# DCAN register map
Vendor: Texas Instruments
Peripheral module from a debugger description file (folder am335x).
Registers are 32-bit, read-only, no defined reset value unless marked. A register's access mark holds for its fields unless they carry their own. Offsets are as the file gives them; lines under a group give offsets from that group; [hi:lo] are bit positions; {n}, {i} and the like mark numbered series; 'fields as' and 'values as' point back to an identical list; <NAME> marks a mode.

## DCAN
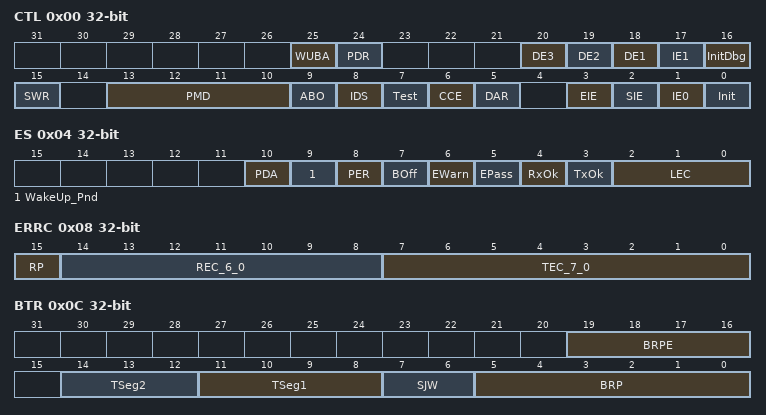
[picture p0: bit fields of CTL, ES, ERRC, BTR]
0x00 CTL access not given — The Bus-Off recovery sequence (refer to CAN specification) cannot be shortened by setting or resetting Init bit. If the module goes Bus-Off, it will automatically set the Init bit and stop all bus activities. When the Init bit is cleared by the application again, the module will then wait for 129 occurrences of Bus Idle (129 * 11 consecutive recessive bits) before resuming normal operation. At the end of the bus-off recovery sequence, the error counters will be reset. After the Init bit is reset, each time when a sequence of 11 recessive bits is monitored, a Bit0 error code is written to the error and status register, enabling the CPU to check whether the CAN bus is stuck at dominant or continuously disturbed, and to monitor the proceeding of the bus-off recovery sequence.
  [25] WUBA rw — Automatic wake up on bus activity when in local power-down mode. Note: The CAN message, which initiates the bus activity, cannot be received. This means that the first message received in power down and automatic wake-up mode, will be lost.
  [24] PDR rw — Request for local low power-down mode
  [20] DE3 rw — Enable DMA request line for IF3. Note: A pending DMA request for IF3 remains active until first access to one of the IF3 registers.
  [19] DE2 rw — Enable DMA request line for IF2. Note: A pending DMA request for IF2 remains active until first access to one of the IF2 registers.
  [18] DE1 rw — Enable DMA request line for IF1. Note: A pending DMA request for IF1 remains active until first access to one of the IF1 registers.
  [17] IE1 rw — Interrupt line 1 enable
  [16] InitDbg ro — Internal init state while debug access
  [15] SWR — SW reset enable. Note: To execute software reset, the following procedure is necessary: (a) Set Init bit to shut down CAN communication and (b) Set SWR bit additionally to Init bit. (access R/WP)
  [13:10] PMD rw — Parity on/off. 5 = Parity function disabled. Others = Parity function enabled.
  [9] ABO rw — Auto-Bus-On enable
  [8] IDS rw — Interruption debug support enable
  [7] Test rw — Test mode enable
  [6] CCE rw — Configuration change enable
  [5] DAR rw — Disable automatic retransmission
  [3] EIE rw — Error interrupt enable
  [2] SIE rw — Status change interrupt enable
  [1] IE0 rw — Interrupt line 0 enable
  [0] Init rw — Initialization
0x04 ES access not given — Interrupts are generated by bits PER, BOff and EWarn (if EIE bit in CAN control register is set) and by bits WakeUpPnd, RxOk, TxOk, and LEC (if SIE bit in CAN control register is set). A change of bit EPass will not generate an interrupt. Reading the error and status register clears the WakeUpPnd, PER, RxOk and TxOk bits and set the LEC to value '7.' Additionally, the status interrupt value (0x8000) in the interrupt register will be replaced by the next lower priority interrupt value. The EOI for all other interrupts (DCANINT0 and DCANINT1) are automatically handled by hardware. For debug support, the auto clear functionality of error and status register (clear of status flags by read) is disabled when in debug/suspend mode.
  [10] PDA ro — Local power-down mode acknowledge
  [9] WakeUp_Pnd — Wake up pending. This bit can be used by the CPU to identify the DCAN as the source to wake up the system. This bit will be reset if error and status register is read. (access R/C)
  [8] PER — Parity error detected. This bit will be reset if error and status register is read. (access R/C)
  [7] BOff ro — Bus-Off state
  [6] EWarn ro — Warning state
  [5] EPass ro — Error passive state
  [4] RxOk — Received a message successfully. This bit will be reset if error and status register is read. (access R/C)
  [3] TxOk — Transmitted a message successfully. This bit will be reset if error and status register is read. (access R/C)
  [2:0] LEC — Last error code. The LEC field indicates the type of the last error on the CAN bus. This field will be cleared to '0' when a message has been transferred (reception or transmission) without error. (access R/S)
0x08 ERRC
  [15] RP — Receive error passive
  [14:8] REC_6_0 — Receive error counter. Actual state of the receive error counter (values from 0 to 255).
  [7:0] TEC_7_0 — Transmit error counter. Actual state of the transmit error counter (values from 0 to 255).
0x0C BTR access not given — This register is only writable if CCE and Init bits in the CAN control register are set. The CAN bit time may be programmed in the range of 8 to 25 time quanta. The CAN time quantum may be programmed in the range of 1 to1024 CAN_CLK periods. With a CAN_CLK of 8 MHz and BRPE = 0x00, the reset value of 0x00002301 configures the DCAN for a bit rate of 500kBit/s.
  [19:16] BRPE ro — Baud rate prescaler extension. Valid programmed values are 0 to 15. By programming BRPE the baud rate prescaler can be extended to values up to 1024.
  [14:12] TSeg2 — Time segment after the sample point. Valid programmed values are 0 to 7. The actual TSeg2 value which is interpreted for the bit timing will be the programmed TSeg2 value + 1. (access R/WP)
  [11:8] TSeg1 — Time segment before the sample point. Valid programmed values are 1 to 15. The actual TSeg1 value interpreted for the bit timing will be the programmed TSeg1 value + 1. (access R/WP)
  [7:6] SJW — Synchronization Jump Width. Valid programmed values are 0 to 3. The actual SJW value interpreted for the synchronization will be the programmed SJW value + 1. (access R/WP)
  [5:0] BRP — Baud rate prescaler. Value by which the CAN_CLK frequency is divided for generating the bit time quanta. The bit time is built up from a multiple of this quanta. Valid programmed values are 0 to 63. The actual BRP value interpreted for the bit timing will be the programmed BRP value + 1. (access R/WP)
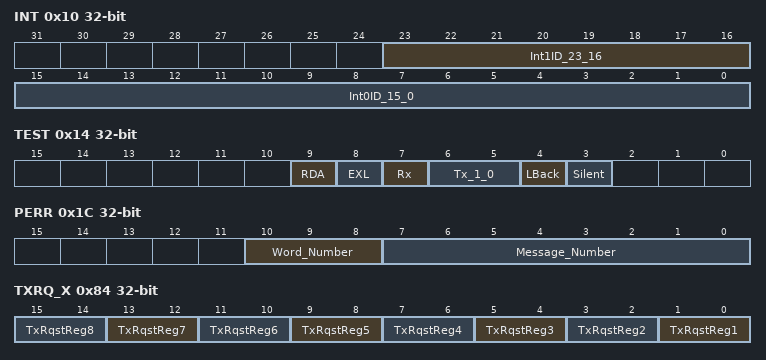
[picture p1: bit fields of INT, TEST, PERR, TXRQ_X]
0x10 INT
  [23:16] Int1ID_23_16 — Interrupt 1 Identifier (indicates the message object with the highest pending interrupt). If several interrupts are pending, the CAN interrupt register will point to the pending interrupt with the highest priority. The DCAN1INT interrupt line remains active until Int1ID reaches value 0 (the cause of the interrupt is reset) or until IE1 is cleared. A message interrupt is cleared by clearing the message object's IntPnd bit. Among the message interrupts, the message object's interrupt priority decreases with increasing message number.
  [15:0] Int0ID_15_0 — Interrupt Identifier (the number here indicates the source of the interrupt). If several interrupts are pending, the CAN interrupt register will point to the pending interrupt with the highest priority. The DCAN0INT interrupt line remains active until Int0ID reaches value 0 (the cause of the interrupt is reset) or until IE0 is cleared. The Status interrupt has the highest priority. Among the message interrupts, the message object's interrupt priority decreases with increasing message number.
0x14 TEST access not given — For all test modes, the test bit in CAN control register needs to be set to one. If test bit is set, the RDA, EXL, Tx1, Tx0, LBack and Silent bits are writable. Bit Rx monitors the state of pin CAN_RX and therefore is only readable. All test register functions are disabled when test bit is cleared. The test register is only writable if test bit in CAN control register is set. Setting Tx[1:0] other than '00' will disturb message transfer. When the internal loop-back mode is active (bit LBack is set), bit EXL will be ignored.
  [9] RDA — RAM direct access enable (access R/WP)
  [8] EXL — External loopback mode (access R/WP)
  [7] Rx ro — Receive pin. Monitors the actual value of the CAN_RX pin
  [6:5] Tx_1_0 — Control of CAN_TX pin. (access R/WP)
  [4] LBack — Loopback mode (access R/WP)
  [3] Silent — Silent mode (access R/WP)
0x1C PERR — If a parity error is detected, the PER flag will be set in the error and status register. This bit is not reset by the parity check mechanism; it must be reset by reading the error and status register. In addition to the PER flag, the parity error code register will indicate the memory area where the parity error has been detected (message number and word number). If more than one word with a parity error was detected, the highest word number with a parity error will be displayed. After a parity error has been detected, the register will hold the last error code until power is removed.
  [10:8] Word_Number — Word number where parity error has been detected.
  [7:0] Message_Number
0x80 ABOTR rw — On write access to the CAN control register while Auto-Bus-On timer is running, the Auto-Bus-On procedure will be aborted. During Debug/Suspend mode, running Auto-Bus-On timer will be paused.
  [31:0] ABO_Time — Number of OCP clock cycles before a Bus-Off recovery sequence is started by clearing the Init bit. This function has to be enabled by setting bit ABO in CAN control register. The Auto-Bus-On timer is realized by a 32 bit counter that starts to count down to zero when the module goes Bus-Off. The counter will be reloaded with the preload value of the ABO time register after this phase.
0x84 TXRQ_X — Example 1. Bit 0 of the transmission request X register represents byte 0 of the transmission request 1 register. If one or more bits in this byte are set, bit 0 of the transmission request X register will be set.
  [2n-1:2n-2] TxRqstReg{n} (n=1..8)
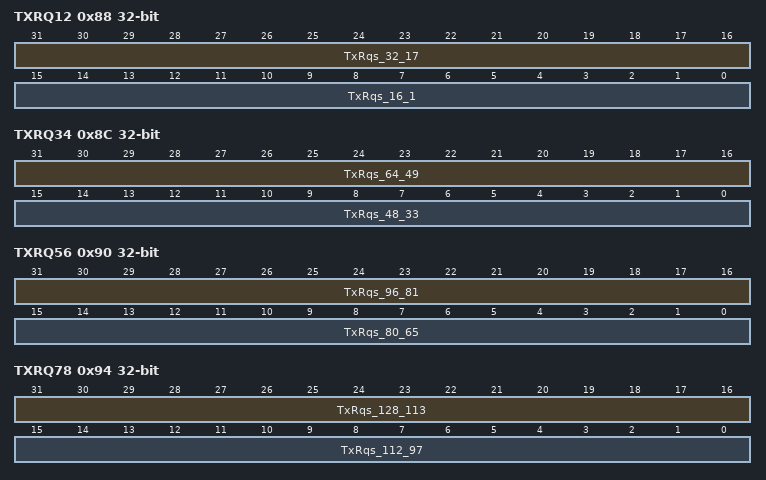
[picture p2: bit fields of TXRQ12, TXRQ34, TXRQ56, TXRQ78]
0x88 TXRQ12 — The TXRQ12 to TXRQ78 registers hold the TxRqst bits of the implemented message objects. By reading out these bits, the CPU can check for pending transmission requests. The TxRqst bit in a specific message object can be set/reset by the CPU via the IF1/IF2 message interface registers, or by the message handler after reception of a remote frame or after a successful transmission.
  [31:16] TxRqs_32_17 — Transmission request bits (for all message objects)
  [15:0] TxRqs_16_1 — Transmission request bits (for all message objects)
0x8C TXRQ34 — The TXRQ12 to TXRQ78 registers hold the TxRqst bits of the implemented message objects. By reading out these bits, the CPU can check for pending transmission requests. The TxRqst bit in a specific message object can be set/reset by the CPU via the IF1/IF2 message interface registers, or by the message handler after reception of a remote frame or after a successful transmission.
  [31:16] TxRqs_64_49 — Transmission request bits (for all message objects)
  [15:0] TxRqs_48_33 — Transmission request bits (for all message objects)
0x90 TXRQ56 — The TXRQ12 to TXRQ78 registers hold the TxRqst bits of the implemented message objects. By reading out these bits, the CPU can check for pending transmission requests. The TxRqst bit in a specific message object can be set/reset by the CPU via the IF1/IF2 message interface registers, or by the message handler after reception of a remote frame or after a successful transmission.
  [31:16] TxRqs_96_81 — Transmission request bits (for all message objects)
  [15:0] TxRqs_80_65 — Transmission request bits (for all message objects)
0x94 TXRQ78 — The TXRQ12 to TXRQ78 registers hold the TxRqst bits of the implemented message objects. By reading out these bits, the CPU can check for pending transmission requests. The TxRqst bit in a specific message object can be set/reset by the CPU via the IF1/IF2 message interface registers, or by the message handler after reception of a remote frame or after a successful transmission.
  [31:16] TxRqs_128_113 — Transmission request bits (for all message objects)
  [15:0] TxRqs_112_97 — Transmission request bits (for all message objects)
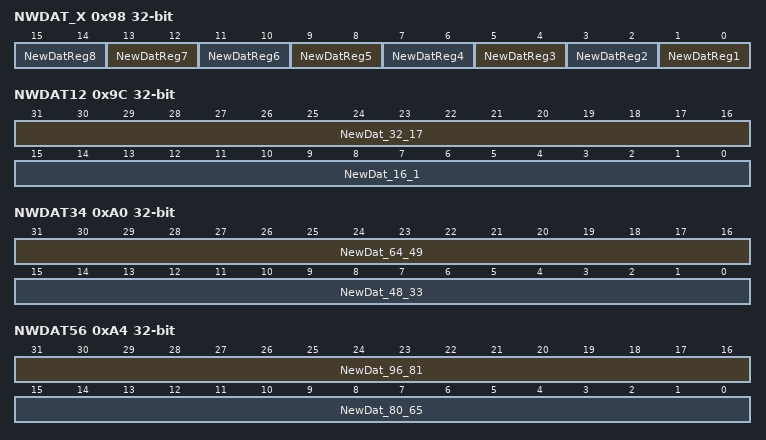
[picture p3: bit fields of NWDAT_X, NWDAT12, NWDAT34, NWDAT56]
0x98 NWDAT_X — With the new data X register, the CPU can detect if one or more bits in the different new data registers are set. Each register bit represents a group of eight message objects. If at least on of the NewDat bits of these message objects are set, the corresponding bit in the new data X register will be set. Example 1. Bit 0 of the new data X register represents byte 0 of the new data 1 register. If one or more bits in this byte are set, bit 0 of the new data X register will be set.
  [2n-1:2n-2] NewDatReg{n} (n=1..8)
0x9C NWDAT12 — These registers hold the NewDat bits of the implemented message objects. By reading out these bits, the CPU can check for new data in the message objects. The NewDat bit of a specific message object can be set/reset by the CPU via the IF1/IF2 interface register sets, or by the message handler after reception of a data frame or after a successful transmission.
  [31:16] NewDat_32_17 — New Data Bits (for all message objects)
  [15:0] NewDat_16_1 — New Data Bits (for all message objects)
0xA0 NWDAT34 — These registers hold the NewDat bits of the implemented message objects. By reading out these bits, the CPU can check for new data in the message objects. The NewDat bit of a specific message object can be set/reset by the CPU via the IF1/IF2 interface register sets, or by the message handler after reception of a data frame or after a successful transmission.
  [31:16] NewDat_64_49 — New Data Bits (for all message objects)
  [15:0] NewDat_48_33 — New Data Bits (for all message objects)
0xA4 NWDAT56 — These registers hold the NewDat bits of the implemented message objects. By reading out these bits, the CPU can check for new data in the message objects. The NewDat bit of a specific message object can be set/reset by the CPU via the IF1/IF2 interface register sets, or by the message handler after reception of a data frame or after a successful transmission.
  [31:16] NewDat_96_81 — New Data Bits (for all message objects)
  [15:0] NewDat_80_65 — New Data Bits (for all message objects)
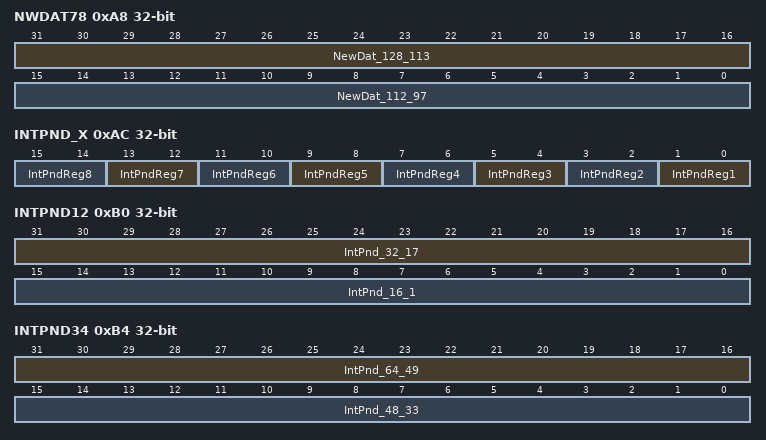
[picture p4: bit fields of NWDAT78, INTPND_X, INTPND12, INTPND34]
0xA8 NWDAT78 — These registers hold the NewDat bits of the implemented message objects. By reading out these bits, the CPU can check for new data in the message objects. The NewDat bit of a specific message object can be set/reset by the CPU via the IF1/IF2 interface register sets, or by the message handler after reception of a data frame or after a successful transmission.
  [31:16] NewDat_128_113 — New Data Bits (for all message objects)
  [15:0] NewDat_112_97 — New Data Bits (for all message objects)
0xAC INTPND_X — With the interrupt pending X register, the CPU can detect if one or more bits in the different interrupt pending registers are set. Each bit of this register represents a group of eight message objects. If at least one of the IntPnd bits of these message objects are set, the corresponding bit in the interrupt pending X register will be set. Example 2. Bit 0 of the interrupt pending X register represents byte 0 of the interrupt pending 1 register. If one or more bits in this byte are set, bit 0 of the interrupt pending X register will be set.
  [2n-1:2n-2] IntPndReg{n} (n=1..8)
0xB0 INTPND12 — These registers hold the IntPnd bits of the implemented message objects. By reading out these bits, the CPU can check for pending interrupts in the message objects. The IntPnd bit of a specific message object can be set/reset by the CPU via the IF1/IF2 interface register sets, or by the message handler after a reception or a successful transmission.
  [31:16] IntPnd_32_17 — Interrupt Pending Bits (for all message objects)
  [15:0] IntPnd_16_1 — Interrupt Pending Bits (for all message objects)
0xB4 INTPND34 — These registers hold the IntPnd bits of the implemented message objects. By reading out these bits, the CPU can check for pending interrupts in the message objects. The IntPnd bit of a specific message object can be set/reset by the CPU via the IF1/IF2 interface register sets, or by the message handler after a reception or a successful transmission.
  [31:16] IntPnd_64_49 — Interrupt Pending Bits (for all message objects)
  [15:0] IntPnd_48_33 — Interrupt Pending Bits (for all message objects)
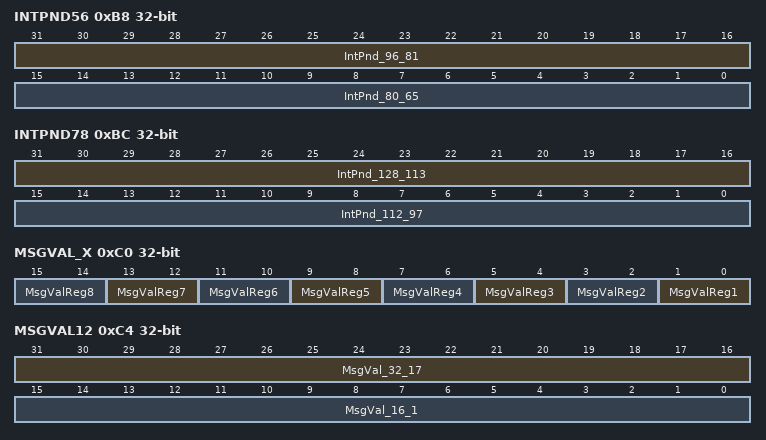
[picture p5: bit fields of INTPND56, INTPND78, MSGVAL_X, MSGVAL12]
0xB8 INTPND56 — These registers hold the IntPnd bits of the implemented message objects. By reading out these bits, the CPU can check for pending interrupts in the message objects. The IntPnd bit of a specific message object can be set/reset by the CPU via the IF1/IF2 interface register sets, or by the message handler after a reception or a successful transmission.
  [31:16] IntPnd_96_81 — Interrupt Pending Bits (for all message objects)
  [15:0] IntPnd_80_65 — Interrupt Pending Bits (for all message objects)
0xBC INTPND78 — These registers hold the IntPnd bits of the implemented message objects. By reading out these bits, the CPU can check for pending interrupts in the message objects. The IntPnd bit of a specific message object can be set/reset by the CPU via the IF1/IF2 interface register sets, or by the message handler after a reception or a successful transmission.
  [31:16] IntPnd_128_113 — Interrupt Pending Bits (for all message objects)
  [15:0] IntPnd_112_97 — Interrupt Pending Bits (for all message objects)
0xC0 MSGVAL_X — With the message valid X register, the CPU can detect if one or more bits in the different message valid registers are set. Each bit of this register represents a group of eight message objects. If at least one of the MsgVal bits of these message objects are set, the corresponding bit in the message valid X register will be set. Example 3. Bit 0 of the message valid X register represents byte 0 of the message valid 1 register. If one or more bits in this byte are set, bit 0 of the message valid X register will be set.
  [2n-1:2n-2] MsgValReg{n} (n=1..8)
0xC4 MSGVAL12 — These registers hold the MsgVal bits of the implemented message objects. By reading out these bits, the CPU can check which message objects are valid. The MsgVal bit of a specific message object can be set/reset by the CPU via the IF1/IF2 interface register sets, or by the message handler after a reception or a successful transmission.
  [31:16] MsgVal_32_17 — Message valid bits (for all message objects)
  [15:0] MsgVal_16_1 — Message valid bits (for all message objects)
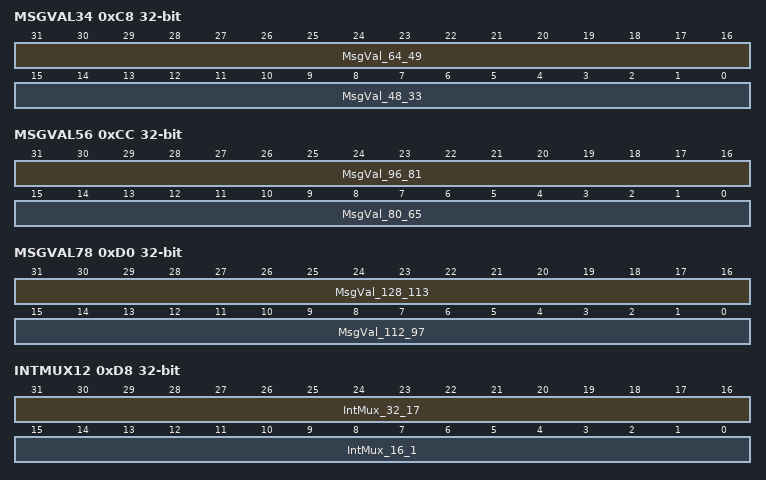
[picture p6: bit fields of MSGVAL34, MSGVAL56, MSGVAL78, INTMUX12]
0xC8 MSGVAL34 — These registers hold the MsgVal bits of the implemented message objects. By reading out these bits, the CPU can check which message objects are valid. The MsgVal bit of a specific message object can be set/reset by the CPU via the IF1/IF2 interface register sets, or by the message handler after a reception or a successful transmission.
  [31:16] MsgVal_64_49 — Message valid bits (for all message objects)
  [15:0] MsgVal_48_33 — Message valid bits (for all message objects)
0xCC MSGVAL56 — These registers hold the MsgVal bits of the implemented message objects. By reading out these bits, the CPU can check which message objects are valid. The MsgVal bit of a specific message object can be set/reset by the CPU via the IF1/IF2 interface register sets, or by the message handler after a reception or a successful transmission.
  [31:16] MsgVal_96_81 — Message valid bits (for all message objects)
  [15:0] MsgVal_80_65 — Message valid bits (for all message objects)
0xD0 MSGVAL78 — These registers hold the MsgVal bits of the implemented message objects. By reading out these bits, the CPU can check which message objects are valid. The MsgVal bit of a specific message object can be set/reset by the CPU via the IF1/IF2 interface register sets, or by the message handler after a reception or a successful transmission.
  [31:16] MsgVal_128_113 — Message valid bits (for all message objects)
  [15:0] MsgVal_112_97 — Message valid bits (for all message objects)
0xD8 INTMUX12 — The IntMux flag determine for each message object, which of the two interrupt lines (DCAN0INT or DCAN1INT) will be asserted when the IntPnd of this message object is set. Both interrupt lines can be globally enabled or disabled by setting or clearing IE0 and IE1 bits in CAN control register. The IntPnd bit of a specific message object can be set or reset by the CPU via the IF1/IF2 interface register sets, or by message handler after reception or successful transmission of a frame. This will also affect the Int0ID resp Int1ID flags in the interrupt register.
  [31:16] IntMux_32_17 — Multiplexes IntPnd value to either DCAN0INT or DCAN1INT interrupt lines (for all message objects)
  [15:0] IntMux_16_1 — Multiplexes IntPnd value to either DCAN0INT or DCAN1INT interrupt lines (for all message objects)
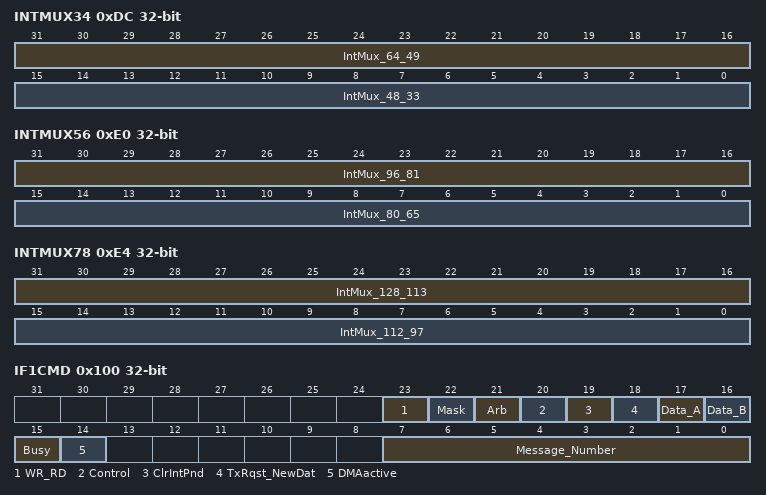
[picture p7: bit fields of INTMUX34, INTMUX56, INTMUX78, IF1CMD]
0xDC INTMUX34 — The IntMux flag determine for each message object, which of the two interrupt lines (DCAN0INT or DCAN1INT) will be asserted when the IntPnd of this message object is set. Both interrupt lines can be globally enabled or disabled by setting or clearing IE0 and IE1 bits in CAN control register. The IntPnd bit of a specific message object can be set or reset by the CPU via the IF1/IF2 interface register sets, or by message handler after reception or successful transmission of a frame. This will also affect the Int0ID resp Int1ID flags in the interrupt register.
  [31:16] IntMux_64_49 — Multiplexes IntPnd value to either DCAN0INT or DCAN1INT interrupt lines (for all message objects)
  [15:0] IntMux_48_33 — Multiplexes IntPnd value to either DCAN0INT or DCAN1INT interrupt lines (for all message objects)
0xE0 INTMUX56 — The IntMux flag determine for each message object, which of the two interrupt lines (DCAN0INT or DCAN1INT) will be asserted when the IntPnd of this message object is set. Both interrupt lines can be globally enabled or disabled by setting or clearing IE0 and IE1 bits in CAN control register. The IntPnd bit of a specific message object can be set or reset by the CPU via the IF1/IF2 interface register sets, or by message handler after reception or successful transmission of a frame. This will also affect the Int0ID resp Int1ID flags in the interrupt register.
  [31:16] IntMux_96_81 — Multiplexes IntPnd value to either DCAN0INT or DCAN1INT interrupt lines (for all message objects)
  [15:0] IntMux_80_65 — Multiplexes IntPnd value to either DCAN0INT or DCAN1INT interrupt lines (for all message objects)
0xE4 INTMUX78 — The IntMux flag determine for each message object, which of the two interrupt lines (DCAN0INT or DCAN1INT) will be asserted when the IntPnd of this message object is set. Both interrupt lines can be globally enabled or disabled by setting or clearing IE0 and IE1 bits in CAN control register. The IntPnd bit of a specific message object can be set or reset by the CPU via the IF1/IF2 interface register sets, or by message handler after reception or successful transmission of a frame. This will also affect the Int0ID resp Int1ID flags in the interrupt register.
  [31:16] IntMux_128_113 — Multiplexes IntPnd value to either DCAN0INT or DCAN1INT interrupt lines (for all message objects)
  [15:0] IntMux_112_97 — Multiplexes IntPnd value to either DCAN0INT or DCAN1INT interrupt lines (for all message objects)
0x100 IF1CMD access not given — The IF1 Command Register (IF1CMD) configures and initiates the transfer between the IF1 register sets and the message RAM. It is configurable which portions of the message object should be transferred. A transfer is started when the CPU writes the message number to bits [7:0] of the IF1 command register. With this write operation, the Busy bit is automatically set to '1' to indicate that a transfer is in progress. After 4 to 14 OCP clock cycles, the transfer between the interface register and the message RAM will be completed and the Busy bit is cleared. The maximum number of cycles is needed when the message transfer concurs with a CAN message transmission, acceptance filtering, or message storage. If the CPU writes to both IF1 command registers consecutively (request of a second transfer while first transfer is still in progress), the second transfer will start after the first one has been completed. While Busy bit is one, IF1 register sets are write protected. For debug support, the auto clear functionality of the IF1 command registers (clear of DMAactive flag by r/w) is disabled during Debug/Suspend mode. If an invalid Message Number is written to bits [7:0] of the IF1 command register, the message handler may access an implemented (valid) message object instead.
  [23] WR_RD — Write/Read (access R/WP)
  [22] Mask — Access mask bits (access R/WP)
  [21] Arb — Access arbitration bits (access R/WP)
  [20] Control — Access control bits. If the TxRqst/NewDat bit in this register(Bit [18]) is set, the TxRqst/ NewDat bit in the IF1 message control register will be ignored. (access R/WP)
  [19] ClrIntPnd — Clear interrupt pending bit (access R/WP)
  [18] TxRqst_NewDat — Access transmission request bit. Note: If a CAN transmission is requested by setting TxRqst/NewDat in this register, the TxRqst/NewDat bits in the message object will be set to one independent of the values in IF1 message control Register. Note: A read access to a message object can be combined with the reset of the control bits IntPnd and NewDat. The values of these bits transferred to the IF1 message control register always reflect the status before resetting them. (access R/WP)
  [17] Data_A — Access Data Bytes 0 to 3. (access R/WP)
  [16] Data_B — Access Data Bytes 4 to 7. (access R/WP)
  [15] Busy — Busy flag. This bit is set to one after the message number has been written to bits 7 to 0. IF1 register set will be write protected. The bit is cleared after read/write action has been finished. (access R/WP)
  [14] DMAactive — Activation of DMA feature for subsequent internal IF1 update. Note: Due to the auto reset feature of the DMAactive bit, this bit has to be set for each subsequent DMA cycle separately. (access R/WP)
  [7:0] Message_Number — Number of message object in message RAM which is used for data transfer. (access R/WP)
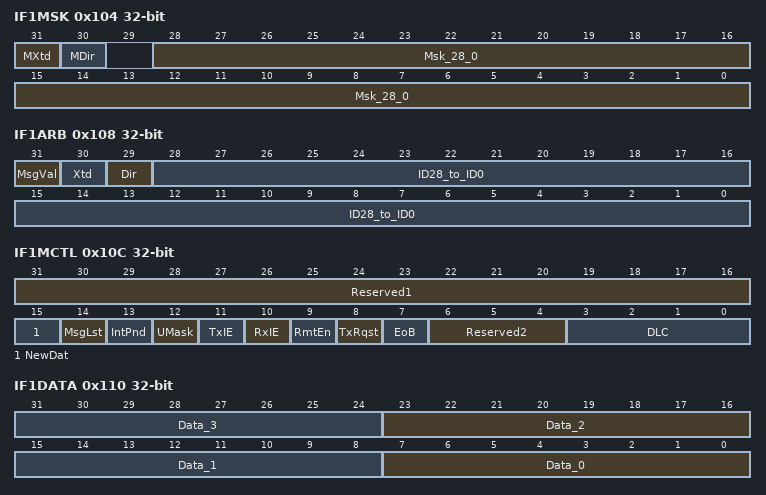
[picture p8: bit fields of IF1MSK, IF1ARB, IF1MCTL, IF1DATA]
0x104 IF1MSK access not given — The bits of the IF1 mask registers mirror the mask bits of a message object. While Busy bit of IF1 command register is one, IF1 register set is write protected.
  [31] MXtd — Mask Extended Identifier. When 11 bit (standard) identifiers are used for a message object, the identifiers of received data frames are written into bits ID28 to ID18. For acceptance filtering, only these bits together with mask bits Msk28 to Msk18 are considered. (access R/WP)
  [30] MDir — Mask Message Direction (access R/WP)
  [28:0] Msk_28_0 — Identifier Mask (access R/WP)
0x108 IF1ARB access not given — The bits of the IF1 arbitration registers mirror the arbitration bits of a message object. While Busy bit of IF1 command register is one, IF1 register set is write protected.
  [31] MsgVal — Message valid. The CPU should reset the MsgVal bit of all unused Messages Objects during the initialization before it resets bit Init in the CAN control register. This bit must also be reset before the identifier ID28 to ID0, the control bits Xtd, Dir or DLC3 to DLC0 are modified, or if the messages object is no longer required. (access R/WP)
  [30] Xtd — Extended identifier (access R/WP)
  [29] Dir — Message direction (access R/WP)
  [28:0] ID28_to_ID0 — Message identifier. ID28 to ID0 is equal to 29 bit identifier (extended frame) ID28 to ID18 is equal to 11 bit identifier (standard frame) (access R/WP)
0x10C IF1MCTL access not given — The bits of the IF1 message control registers mirror the message control bits of a message object. While Busy bit of IF1 command register is one, IF1 register set is write protected.
  [31:16] Reserved1 — (access R/WP)
  [15] NewDat — New data (access R/WP)
  [14] MsgLst — Message lost (only valid for message objects with direction = receive) (access R/WP)
  [13] IntPnd — Interrupt pending (access R/WP)
  [12] UMask — Use acceptance mask. If the UMask bit is set to one, the message object's mask bits have to be programmed during initialization of the message object before MsgVal is set to one. (access R/WP)
  [11] TxIE — Transmit interrupt enable (access R/WP)
  [10] RxIE — Receive interrupt enable (access R/WP)
  [9] RmtEn — Remote enable (access R/WP)
  [8] TxRqst — Transmit request (access R/WP)
  [7] EoB — Data frame has 0 to 8 data bits. Note: This bit is used to concatenate multiple message objects to build a FIFO Buffer. For single message objects (not belonging to a FIFO Buffer), this bit must always be set to one. (access R/WP)
  [6:4] Reserved2 — (access R/WP)
  [3:0] DLC — Data length code. Note: The data length code of a message object must be defined the same as in all the corresponding objects with the same identifier at other nodes. When the message handler stores a data frame, it will write the DLC to the value given by the received message. (access R/WP)
0x110 IF1DATA access not given — The data bytes of CAN messages are stored in the IF1 registers in the following order: (1) In a CAN data frame, Data 0 is the first, and Data 7 is the last byte to be transmitted or received. (2) In CAN's serial bit stream, the MSB of each byte will be transmitted first.
  [8n+7:8n] Data_{n} (n=0..3) — Data {n}. (access R/WP)
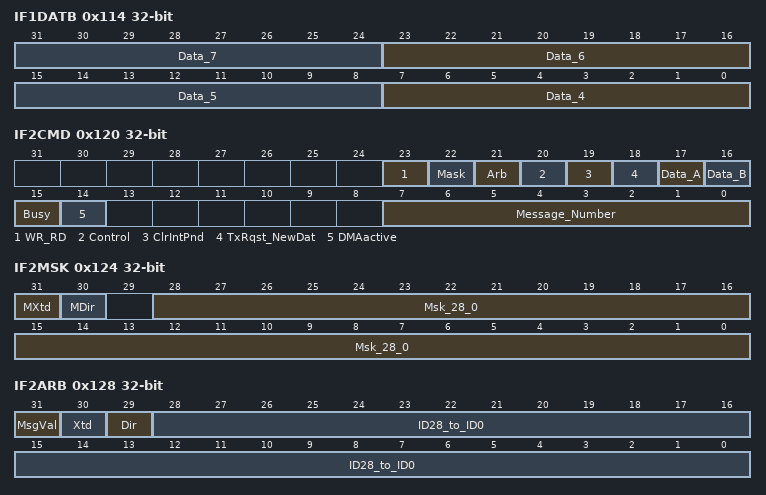
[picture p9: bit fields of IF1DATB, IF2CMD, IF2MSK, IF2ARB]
0x114 IF1DATB access not given — The data bytes of CAN messages are stored in the IF1 registers in the following order: (1) In a CAN data frame, Data 0 is the first, and Data 7 is the last byte to be transmitted or received. (2) In CAN's serial bit stream, the MSB of each byte will be transmitted first.
  [8n-25:8n-32] Data_{n} (n=4..7) — Data {n}. (access R/WP)
0x120 IF2CMD access not given — The IF2 Command Register (IF1CMD) configures and initiates the transfer between the IF2 register sets and the message RAM. It is configurable which portions of the message object should be transferred. A transfer is started when the CPU writes the message number to bits [7:0] of the IF2 command register. With this write operation, the Busy bit is automatically set to '1' to indicate that a transfer is in progress. After 4 to 14 OCP clock cycles, the transfer between the interface register and the message RAM will be completed and the Busy bit is cleared. The maximum number of cycles is needed when the message transfer concurs with a CAN message transmission, acceptance filtering, or message storage. If the CPU writes to both IF2 command registers consecutively (request of a second transfer while first transfer is still in progress), the second transfer will start after the first one has been completed. While Busy bit is one, IF2 register sets are write protected. For debug support, the auto clear functionality of the IF2 command registers (clear of DMAactive flag by r/w) is disabled during Debug/Suspend mode. If an invalid Message Number is written to bits [7:0] of the IF2 command register, the message handler may access an implemented (valid) message object instead.
  [23] WR_RD — Write/Read (access R/WP)
  [22] Mask — Access mask bits (access R/WP)
  [21] Arb — Access arbitration bits (access R/WP)
  [20] Control — Access control bits. If the TxRqst/NewDat bit in this register(Bit [18]) is set, the TxRqst/ NewDat bit in the IF2 message control register will be ignored. (access R/WP)
  [19] ClrIntPnd — Clear interrupt pending bit (access R/WP)
  [18] TxRqst_NewDat — Access transmission request bit. Note: If a CAN transmission is requested by setting TxRqst/NewDat in this register, the TxRqst/NewDat bits in the message object will be set to one independent of the values in IF2 message control Register. Note: A read access to a message object can be combined with the reset of the control bits IntPnd and NewDat. The values of these bits transferred to the IF2 message control register always reflect the status before resetting them. (access R/WP)
  [17] Data_A — Access Data Bytes 0 to 3. (access R/WP)
  [16] Data_B — Access Data Bytes 4 to 7. (access R/WP)
  [15] Busy — Busy flag. This bit is set to one after the message number has been written to bits 7 to 0. IF2 register set will be write protected. The bit is cleared after read/write action has been finished. (access R/WP)
  [14] DMAactive — Activation of DMA feature for subsequent internal IF2 update. Note: Due to the auto reset feature of the DMAactive bit, this bit has to be set for each subsequent DMA cycle separately. (access R/WP)
  [7:0] Message_Number — Number of message object in message RAM which is used for data transfer. (access R/WP)
0x124 IF2MSK access not given — The bits of the IF2 mask registers mirror the mask bits of a message object. While Busy bit of IF2 command register is one, IF2 register set is write protected.
  fields as IF1MSK
0x128 IF2ARB access not given — The bits of the IF2 arbitration registers mirror the arbitration bits of a message object. While Busy bit of IF2 command register is one, IF2 register set is write protected.
  [31] MsgVal — Message valid. The CPU should reset the MsgVal bit of all unused Messages Objects during the initialization before it resets bit Init in the CAN control register. This bit must also be reset before the identifier ID28 to ID0, the control bits Xtd, Dir or DLC3 to DLC0 are modified, or if the messages object is no longer required. (access R/WP)
  [30] Xtd — Extended identifier (access R/WP)
  [29] Dir — Message direction (access R/WP)
  [28:0] ID28_to_ID0 — Message identifier. ID28 to ID0 is equal to 29-bit identifier (extended frame) ID28 to ID18 is equal to 11-bit identifier (standard frame) (access R/WP)
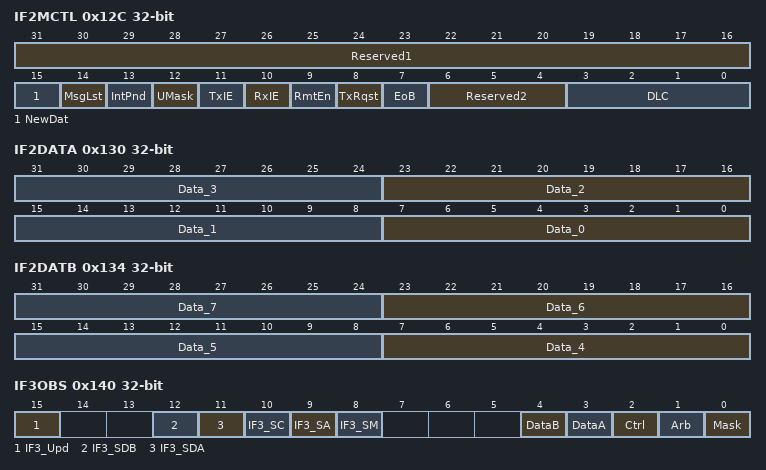
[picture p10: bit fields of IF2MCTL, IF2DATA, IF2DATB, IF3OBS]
0x12C IF2MCTL access not given — The bits of the IF2 message control registers mirror the message control bits of a message object. While Busy bit of IF2 command register is one, IF2 register set is write protected.
  fields as IF1MCTL
0x130 IF2DATA access not given — The data bytes of CAN messages are stored in the IF2 registers in the following order: (1) In a CAN data frame, Data 0 is the first, and Data 7 is the last byte to be transmitted or received. (2) In CAN's serial bit stream, the MSB of each byte will be transmitted first.
  [8n+7:8n] Data_{n} (n=0..3) — Data {n}. (access R/WP)
0x134 IF2DATB access not given — The data bytes of CAN messages are stored in the IF2 registers in the following order: (1) In a CAN data frame, Data 0 is the first, and Data 7 is the last byte to be transmitted or received. (2) In CAN's serial bit stream, the MSB of each byte will be transmitted first.
  [8n-25:8n-32] Data_{n} (n=4..7) — Data {n}. (access R/WP)
0x140 IF3OBS access per field — The IF3 register set can automatically be updated with received message objects without the need to initiate the transfer from message RAM by CPU. The observation flags (Bits [4:0]) in the IF3 observation register are used to determine, which data sections of the IF3 interface register set have to be read in order to complete a DMA read cycle. After all marked data sections are read, the DCAN is enabled to update the IF3 interface register set with new data. Any access order of single bytes or half-words is supported. When using byte or half-word accesses, a data section is marked as completed, if all bytes are read. Note: If IF3 Update Enable is used and no Observation flag is set, the corresponding message objects will be copied to IF3 without activating the DMA request line and without waiting for DMA read accesses. A write access to this register aborts a pending DMA cycle by resetting the DMA line and enables updating of IF3 interface register set with new data. To avoid data inconsistency, the DMA controller should be disabled before reconfiguring IF3 observation register. The status of the current read-cycle can be observed via status flags (Bits [12:8]). If an interrupt line is available for IF3, an interrupt will be generated by IF3Upd flag. See the device-specific data sheet for the availability of this interrupt source. With this interrupt, the observation status bits and the IF3Upd bit could be used by the application to realize the notification about new IF3 content in polling or interrupt mode.
  [15] IF3_Upd ro — IF3 Update Data
  [12] IF3_SDB ro — IF3 Status of Data B read access
  [11] IF3_SDA ro — IF3 Status of Data A read access
  [10] IF3_SC ro — IF3 Status of control bits read access
  [9] IF3_SA ro — IF3 Status of Arbitration data read access
  [8] IF3_SM ro — IF3 Status of Mask data read access
  [4] DataB rw — Data B read observation
  [3] DataA rw — Data A read observation
  [2] Ctrl rw — Ctrl read observation
  [1] Arb rw — Arbitration data read observation
  [0] Mask rw — Mask data read observation
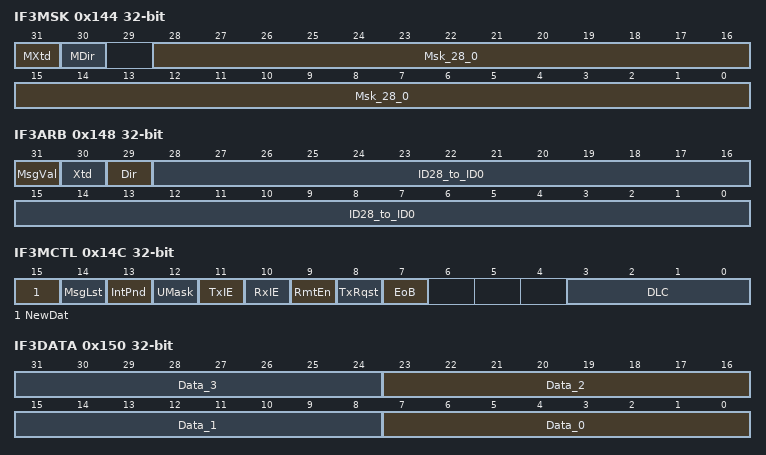
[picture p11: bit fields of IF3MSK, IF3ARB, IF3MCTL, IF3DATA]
0x144 IF3MSK access not given
  [31] MXtd ro — Mask Extended Identifier. When 11 bit (standard) identifiers are used for a message object, the identifiers of received data frames are written into bits ID28 to ID18. For acceptance filtering, only these bits together with mask bits Msk28 to Msk18 are considered.
  [30] MDir ro — Mask Message Direction
  [28:0] Msk_28_0 — Identifier Mask (access R/WP)
0x148 IF3ARB
  [31] MsgVal — Message Valid. The CPU should reset the MsgVal bit of all unused Messages Objects during the initialization before it resets bit Init in the CAN control register. This bit must also be reset before the identifier ID28 to ID0, the control bits Xtd, Dir or DLC3 to DLC0 are modified, or if the messages object is no longer required.
  [30] Xtd — Extended Identifier
  [29] Dir — Message Direction
  [28:0] ID28_to_ID0 — Message Identifier. ID28 to ID0 is equal to 29 bit Identifier (extended frame). ID28 to ID18 is equal to 11 bit Identifier (standard frame).
0x14C IF3MCTL
  [15] NewDat — New Data
  [14] MsgLst — Message Lost (only valid for message objects with direction = receive)
  [13] IntPnd — Interrupt Pending
  [12] UMask — Use Acceptance Mask
  [11] TxIE — Transmit Interrupt enable
  [10] RxIE — Receive Interrupt enable
  [9] RmtEn — Remote enable
  [8] TxRqst — Transmit Request
  [7] EoB — Data frame has 0 to 8 data bits. Note: This bit is used to concatenate multiple message objects to build a FIFO Buffer. For single message objects (not belonging to a FIFO Buffer), this bit must always be set to one.
  [3:0] DLC — Data Length Code. Note: The data length code of a message object must be defined the same as in all the corresponding objects with the same identifier at other nodes. When the message handler stores a data frame, it will write the DLC to the value given by the received message.
0x150 IF3DATA — The data bytes of CAN messages are stored in the IF3 registers in the following order. In a CAN data frame, Data 0 is the first, and Data 7 is the last byte to be transmitted or received. In CAN's serial bit stream, the MSB of each byte will be transmitted first.
  [8n+7:8n] Data_{n} (n=0..3)
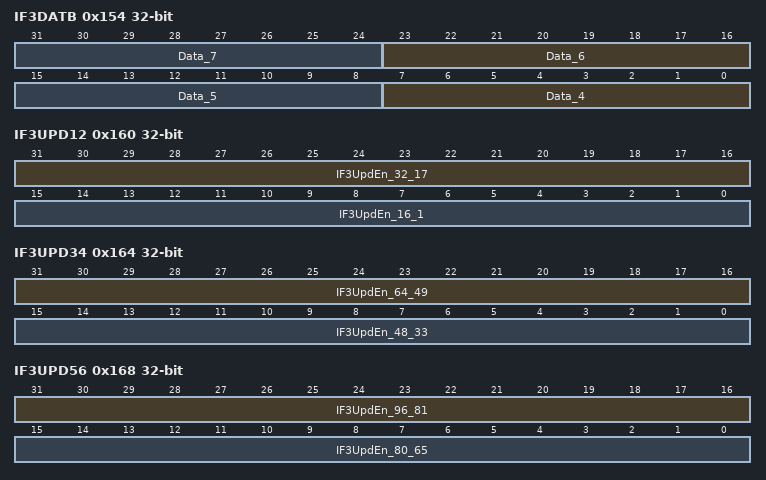
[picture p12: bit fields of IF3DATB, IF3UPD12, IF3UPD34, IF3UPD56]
0x154 IF3DATB — The data bytes of CAN messages are stored in the IF3 registers in the following order. In a CAN data frame, Data 0 is the first, and Data 7 is the last byte to be transmitted or received. In CAN's serial bit stream, the MSB of each byte will be transmitted first.
  [8n-25:8n-32] Data_{n} (n=4..7)
0x160 IF3UPD12 rw — The automatic update functionality of the IF3 register set can be configured for each message object. A message object is enabled for automatic IF3 update, if the dedicated IF3UpdEn flag is set. This means that an active NewDat flag of this message object (e.g due to reception of a CAN frame) will trigger an automatic copy of the whole message object to IF3 register set. IF3 Update enable should not be set for transmit objects.
  [31:16] IF3UpdEn_32_17 — IF3 Update Enabled (for all message objects)
  [15:0] IF3UpdEn_16_1 — IF3 Update Enabled (for all message objects)
0x164 IF3UPD34 rw — The automatic update functionality of the IF3 register set can be configured for each message object. A message object is enabled for automatic IF3 update, if the dedicated IF3UpdEn flag is set. This means that an active NewDat flag of this message object (e.g due to reception of a CAN frame) will trigger an automatic copy of the whole message object to IF3 register set. IF3 Update enable should not be set for transmit objects.
  [31:16] IF3UpdEn_64_49 — IF3 Update Enabled (for all message objects)
  [15:0] IF3UpdEn_48_33 — IF3 Update Enabled (for all message objects)
0x168 IF3UPD56 rw — The automatic update functionality of the IF3 register set can be configured for each message object. A message object is enabled for automatic IF3 update, if the dedicated IF3UpdEn flag is set. This means that an active NewDat flag of this message object (e.g due to reception of a CAN frame) will trigger an automatic copy of the whole message object to IF3 register set. IF3 Update enable should not be set for transmit objects.
  [31:16] IF3UpdEn_96_81 — IF3 Update Enabled (for all message objects)
  [15:0] IF3UpdEn_80_65 — IF3 Update Enabled (for all message objects)
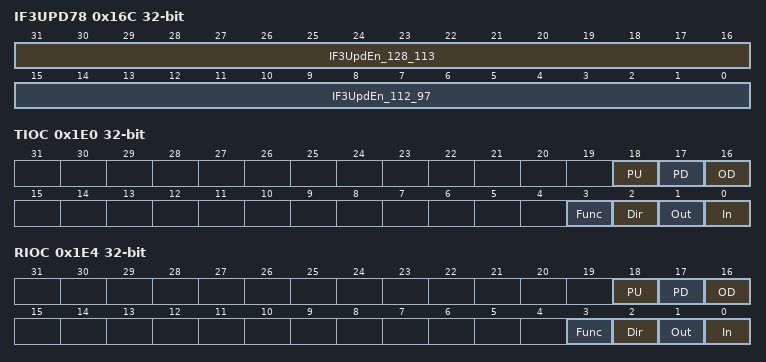
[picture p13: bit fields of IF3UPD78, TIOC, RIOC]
0x16C IF3UPD78 rw — The automatic update functionality of the IF3 register set can be configured for each message object. A message object is enabled for automatic IF3 update, if the dedicated IF3UpdEn flag is set. This means that an active NewDat flag of this message object (e.g due to reception of a CAN frame) will trigger an automatic copy of the whole message object to IF3 register set. IF3 Update enable should not be set for transmit objects.
  [31:16] IF3UpdEn_128_113 — IF3 Update Enabled (for all message objects)
  [15:0] IF3UpdEn_112_97 — IF3 Update Enabled (for all message objects)
0x1E0 TIOC access not given — The CAN_TX pin of the DCAN module can be used as general purpose IO pin if CAN function is not needed. The values of the IO control registers are only writable if Init bit of the CAN control register is set. The OD, Func, Dir and Out bits of the CAN TX IO control register are forced to certain values when Init bit of CAN control register is reset (see bit descriptions).
  [18] PU rw — CAN_TX pull up/pull down select. This bit is only active when CAN_TX is configured to be an input.
  [17] PD rw — CAN_TX pull disable. This bit is only active when CAN_TX is configured to be an input.
  [16] OD — CAN_TX open drain enable. This bit is only active when CAN_TX is configured to be in GIO mode (TIOC.Func=0). Forced to '0' if Init bit of CAN control register is reset. (access R/WP)
  [3] Func — CAN_TX function. This bit changes the function of the CAN_TX pin. Forced to '1' if Init bit of CAN control register is reset. (access R/WP)
  [2] Dir — CAN_TX data direction. This bit controls the direction of the CAN_TX pin when it is configured to be in GIO mode only (TIOC.Func=0). Forced to '1' if Init bit of CAN control register is reset. (access R/WP)
  [1] Out — CAN_TX data out write. This bit is only active when CAN_TX pin is configured to be in GIO mode (TIOC.Func = 0) and configured to be an output pin (TIOC.Dir = 1). The value of this bit indicates the value to be output to the CAN_TX pin. Forced to Tx output of the CAN core, if Init bit of CAN control register is reset. (access R/WP)
  [0] In ro — CAN_TX data in. Note: When CAN_TX pin is connected to a CAN transceiver, an external pullup resistor has to be used to ensure that the CAN bus will not be disturbed (e.g. while reset of the DCAN module).
0x1E4 RIOC access not given — The CAN_RX pin of the DCAN module can be used as general purpose IO pin if CAN function is not needed. The values of the IO control registers are writable only if Init bit of CAN control register is set. The OD, Func and Dir bits of the CAN RX IO control register are forced to certain values when the Init bit of CAN control register is reset (see bit descriptions).
  [18] PU rw — CAN_RX pull up/pull down select. This bit is only active when CAN_RX is configured to be an input.
  [17] PD rw — CAN_RX pull disable. This bit is only active when CAN_TX is configured to be an input.
  [16] OD — CAN_RX open drain enable. This bit is only active when CAN_RX is configured to be in GIO mode (TIOC.Func=0). Forced to '0' if Init bit of CAN control register is reset. (access R/WP)
  [3] Func — CAN_RX function. This bit changes the function of the CAN_RX pin. Forced to '1' if Init bit of CAN control register is reset. (access R/WP)
  [2] Dir — CAN_RX data direction. This bit controls the direction of the CAN_RX pin when it is configured to be in GIO mode only (TIOC.Func=0). Forced to '1' if Init bit of CAN control register is reset. (access R/WP)
  [1] Out — CAN_RX data out write. This bit is only active when CAN_RX pin is configured to be in GIO mode (TIOC.Func = 0) and configured to be an output pin (TIOC.Dir = 1). The value of this bit indicates the value to be output to the CAN_RX pin. Forced to Tx output of the CAN core, if Init bit of CAN control register is reset. (access R/WP)
  [0] In ro — CAN_RX data in. Note: When CAN_RX pin is connected to a CAN transceiver, an external pullup resistor has to be used to ensure that the CAN bus will not be disturbed (for example, while reset of the DCAN module).
